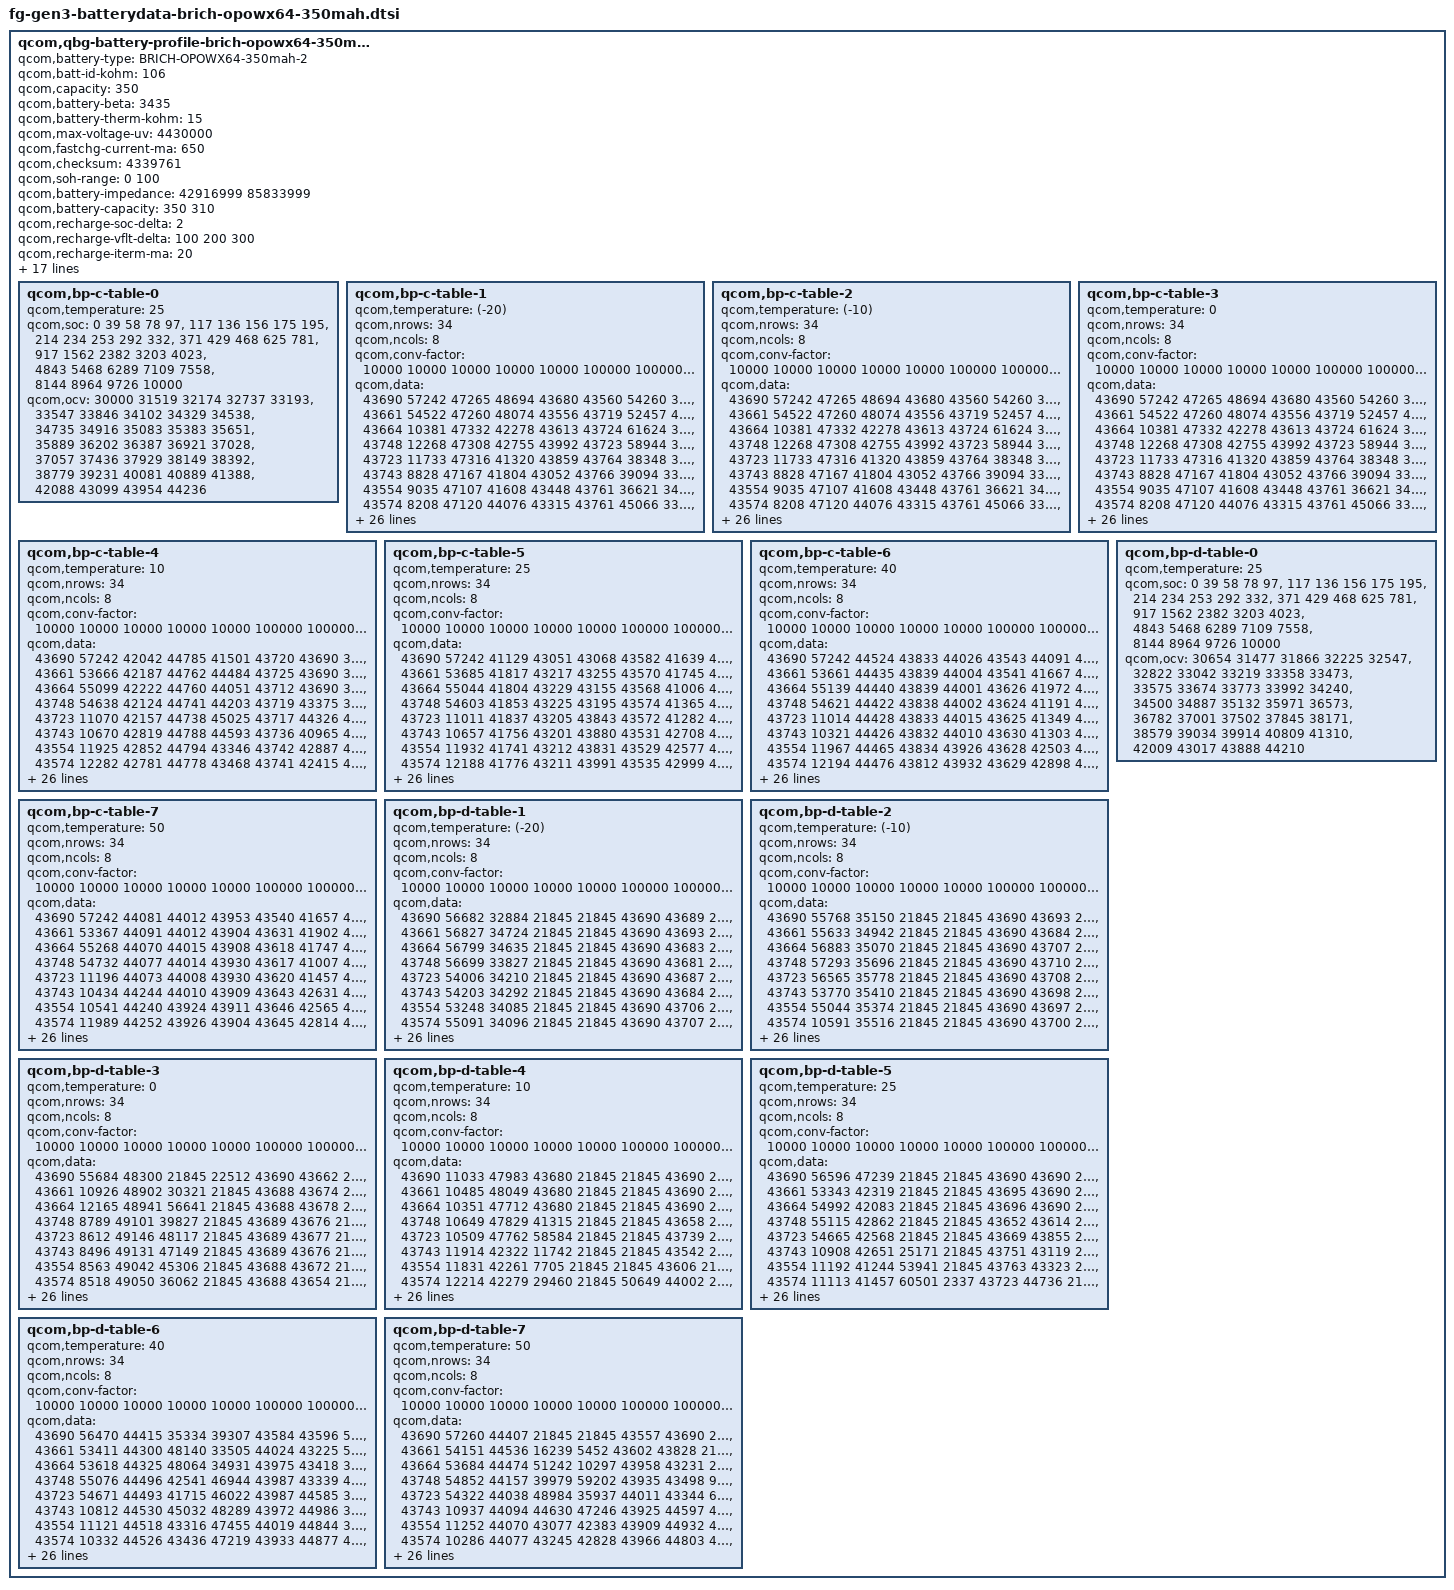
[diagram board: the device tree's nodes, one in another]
qcom,qbg-battery-profile-brich-opowx64-350mAh {
	qcom,battery-type = "BRICH-OPOWX64-350mah-2";
	qcom,batt-id-kohm = <106>;
	qcom,capacity = <350>;
	qcom,battery-beta = <3435>;
	qcom,battery-therm-kohm = <15>;
	qcom,max-voltage-uv = <4430000>;
	qcom,fastchg-current-ma = <650>;
	qcom,checksum = <4339761>; /*@5, 0.008V, 8.0% */
	qcom,soh-range = <0 100>;
	/* Nominal_Impedance in 10nohm @ SOC 50% 25C* 0:fresh cell, 1: aged cell */
	qcom,battery-impedance = <42916999 85833999>;
	/* Nominal_Capacity in mAh. 0: fresh cell, 1:aged cell */
	qcom,battery-capacity = <350 310>;
	/* SOC delta (in percent) dropped from EOC SOC to enable recharge */
	qcom,recharge-soc-delta =<2>;
	/* vfloat delta (in mV) dropped from regular vfloat in recharge */
	qcom,recharge-vflt-delta =<100 200 300>;
	/* Termination current (in mA) in recharge */
	qcom,recharge-iterm-ma = <20>;
	qcom,batt-temp-coeffs =    <0 70 120 170 430 435 440 530>;
	qcom,batt-current-coeffs = <0 150000 225000 300000 650000 350000 100000 100000>;
	qcom,batt-max-mv-coeffs = <4130000 4430000>;
	qcom,chg-limit-current-default = <100000 150000>;

	qcom,jeita-fcc-ranges = <0  70  150000
                                71 440  650000
                                441 530 100000>;

    	qcom,jeita-fv-ranges = <0   70  4430000
                           	71 440  4430000
                           	441 530 4130000>;
				
	qcom,step-chg-ranges = <3400000  4250000  650000
				4250001  4350000  650000
				4350001  4430000  650000>;

    /* COOL = 15 DegC, WARM = 70 DegC */
    qcom,jeita-soft-thresholds = <0x30DD 0x7BC>;
    /* COLD = 0 DegC, HOT = 80 DegC */
    qcom,jeita-hard-thresholds = <0x3733 0x5ed>;
    /* COOL = 18 DegC, WARM = 39 DegC*/
    qcom,jeita-soft-hys-thresholds = <0x256e 0x161b>;
    qcom,jeita-soft-fcc-ua = <150000 100000>;
    qcom,jeita-soft-fv-uv = <4430000 4430000>;

	qcom,bp-c-table-0 {
		qcom,temperature = <25>;
		qcom,soc = <    0    39    58    78    97>,
			<  117   136   156   175   195>,
			<  214   234   253   292   332>,
			<  371   429   468   625   781>,
			<  917  1562  2382  3203  4023>,
			< 4843  5468  6289  7109  7558>,
			< 8144  8964  9726 10000>;
		qcom,ocv = <30000 31519 32174 32737 33193>,
			<33547 33846 34102 34329 34538>,
			<34735 34916 35083 35383 35651>,
			<35889 36202 36387 36921 37028>,
			<37057 37436 37929 38149 38392>,
			<38779 39231 40081 40889 41388>,
			<42088 43099 43954 44236>;
	};

	qcom,bp-c-table-1 {
		qcom,temperature = <(-20)>;
		qcom,nrows = <34>;
		qcom,ncols = <8>;
		qcom,conv-factor = <10000 10000 10000 10000 10000 100000 100000 10000>;
		qcom,data = <43690 57242 47265 48694 43680 43560 54260 37818>,
			<43661 54522 47260 48074 43556 43719 52457 40812>,
			<43664 10381 47332 42278 43613 43724 61624 39259>,
			<43748 12268 47308 42755 43992 43723 58944 39098>,
			<43723 11733 47316 41320 43859 43764 38348 39578>,
			<43743  8828 47167 41804 43052 43766 39094 33995>,
			<43554  9035 47107 41608 43448 43761 36621 34309>,
			<43574  8208 47120 44076 43315 43761 45066 33153>,
			<43525  8666 47213 44983 44729 43766 47882 33608>,
			<43625  9892 47204 43357 44752 43767 41365 33353>,
			<43644  9739 47226 43446 44647 43764 44360 33437>,
			<43584 10114 47204 43239 44933 43720 45014 36121>,
			<43607  9992 47200 43820 44854 43725 43486 36334>,
			<43918  9438 47125 43714 44268 43737 43590 35893>,
			<44006  9612 47105 43664 44286 43735 43531 35998>,
			<43993  9581 47144 43678 44264 43554 43531 36684>,
			<43783 15093 47353 43672 44189 43579 43531 36667>,
			<43902 14909 47342 43672 44182 43576 43573 36812>,
			<43227 14918 47302 43753 44279 43733 43532 36784>,
			<43431 15295 47351 43008 44764 43734 43471 36859>,
			<43327 15255 47262 44952 43260 43563 44384 36619>,
			<44208 14777 47293 44287 44735 43552 41203 35951>,
			<41956 15995 47938 44120 44160 43578 41196 36101>,
			<42537 16171 47928 44485 44157 43578 41066 36166>,
			<42269 15552 47905 44402 44132 43558 41803 36217>,
			<47169 15722 47919 44348 41641 43558 44486 33437>,
			<49142 13269 47918 44342 44522 43555 41813 36286>,
			<45627 13836 47701 44510 44827 43567 44191 36370>,
			<45423 13595 47698 44393 44956 43560 44122 36562>,
			<46892  2858 47687 44380 44996 43563 44241 36445>,
			<46458  3749 47685 41678 44868 43562 44196 35981>,
			<35246  3445 48005 41559 40979 43563 43342 34028>,
			<36692   492 47978 44121 48695 43560 43136 36954>,
			<36282  1778 48083 44684 48125 43712 43933 40443>;
	};

	qcom,bp-c-table-2 {
		qcom,temperature = <(-10)>;
		qcom,nrows = <34>;
		qcom,ncols = <8>;
		qcom,conv-factor = <10000 10000 10000 10000 10000 100000 100000 10000>;
		qcom,data = <43690 57242 47265 48694 43680 43560 54260 37818>,
			<43661 54522 47260 48074 43556 43719 52457 40812>,
			<43664 10381 47332 42278 43613 43724 61624 39259>,
			<43748 12268 47308 42755 43992 43723 58944 39098>,
			<43723 11733 47316 41320 43859 43764 38348 39578>,
			<43743  8828 47167 41804 43052 43766 39094 33995>,
			<43554  9035 47107 41608 43448 43761 36621 34309>,
			<43574  8208 47120 44076 43315 43761 45066 33153>,
			<43525  8666 47213 44983 44729 43766 47882 33608>,
			<43625  9892 47204 43357 44752 43767 41365 33353>,
			<43644  9739 47226 43446 44647 43764 44360 33437>,
			<43584 10114 47204 43239 44933 43720 45014 36121>,
			<43607  9992 47200 43820 44854 43725 43486 36334>,
			<43918  9438 47125 43714 44268 43737 43590 35893>,
			<44006  9612 47105 43664 44286 43735 43531 35998>,
			<43993  9581 47144 43678 44264 43554 43531 36684>,
			<43783 15093 47353 43672 44189 43579 43531 36667>,
			<43902 14909 47342 43672 44182 43576 43573 36812>,
			<43227 14918 47302 43753 44279 43733 43532 36784>,
			<43431 15295 47351 43008 44764 43734 43471 36859>,
			<43327 15255 47262 44952 43260 43563 44384 36619>,
			<44208 14777 47293 44287 44735 43552 41203 35951>,
			<41956 15995 47938 44120 44160 43578 41196 36101>,
			<42537 16171 47928 44485 44157 43578 41066 36166>,
			<42269 15552 47905 44402 44132 43558 41803 36217>,
			<47169 15722 47919 44348 41641 43558 44486 33437>,
			<49142 13269 47918 44342 44522 43555 41813 36286>,
			<45627 13836 47701 44510 44827 43567 44191 36370>,
			<45423 13595 47698 44393 44956 43560 44122 36562>,
			<46892  2858 47687 44380 44996 43563 44241 36445>,
			<46458  3749 47685 41678 44868 43562 44196 35981>,
			<35246  3445 48005 41559 40979 43563 43342 34028>,
			<36692   492 47978 44121 48695 43560 43136 36954>,
			<36282  1778 48083 44684 48125 43712 43933 40443>;
	};

	qcom,bp-c-table-3 {
		qcom,temperature = <0>;
		qcom,nrows = <34>;
		qcom,ncols = <8>;
		qcom,conv-factor = <10000 10000 10000 10000 10000 100000 100000 10000>;
		qcom,data = <43690 57242 47265 48694 43680 43560 54260 37818>,
			<43661 54522 47260 48074 43556 43719 52457 40812>,
			<43664 10381 47332 42278 43613 43724 61624 39259>,
			<43748 12268 47308 42755 43992 43723 58944 39098>,
			<43723 11733 47316 41320 43859 43764 38348 39578>,
			<43743  8828 47167 41804 43052 43766 39094 33995>,
			<43554  9035 47107 41608 43448 43761 36621 34309>,
			<43574  8208 47120 44076 43315 43761 45066 33153>,
			<43525  8666 47213 44983 44729 43766 47882 33608>,
			<43625  9892 47204 43357 44752 43767 41365 33353>,
			<43644  9739 47226 43446 44647 43764 44360 33437>,
			<43584 10114 47204 43239 44933 43720 45014 36121>,
			<43607  9992 47200 43820 44854 43725 43486 36334>,
			<43918  9438 47125 43714 44268 43737 43590 35893>,
			<44006  9612 47105 43664 44286 43735 43531 35998>,
			<43993  9581 47144 43678 44264 43554 43531 36684>,
			<43783 15093 47353 43672 44189 43579 43531 36667>,
			<43902 14909 47342 43672 44182 43576 43573 36812>,
			<43227 14918 47302 43753 44279 43733 43532 36784>,
			<43431 15295 47351 43008 44764 43734 43471 36859>,
			<43327 15255 47262 44952 43260 43563 44384 36619>,
			<44208 14777 47293 44287 44735 43552 41203 35951>,
			<41956 15995 47938 44120 44160 43578 41196 36101>,
			<42537 16171 47928 44485 44157 43578 41066 36166>,
			<42269 15552 47905 44402 44132 43558 41803 36217>,
			<47169 15722 47919 44348 41641 43558 44486 33437>,
			<49142 13269 47918 44342 44522 43555 41813 36286>,
			<45627 13836 47701 44510 44827 43567 44191 36370>,
			<45423 13595 47698 44393 44956 43560 44122 36562>,
			<46892  2858 47687 44380 44996 43563 44241 36445>,
			<46458  3749 47685 41678 44868 43562 44196 35981>,
			<35246  3445 48005 41559 40979 43563 43342 34028>,
			<36692   492 47978 44121 48695 43560 43136 36954>,
			<36282  1778 48083 44684 48125 43712 43933 40443>;
	};

	qcom,bp-c-table-4 {
		qcom,temperature = <10>;
		qcom,nrows = <34>;
		qcom,ncols = <8>;
		qcom,conv-factor = <10000 10000 10000 10000 10000 100000 100000 10000>;
		qcom,data = <43690 57242 42042 44785 41501 43720 43690 36500>,
			<43661 53666 42187 44762 44484 43725 43690 34999>,
			<43664 55099 42222 44760 44051 43712 43690 35748>,
			<43748 54638 42124 44741 44203 43719 43375 35497>,
			<43723 11070 42157 44738 45025 43717 44326 46507>,
			<43743 10670 42819 44788 44593 43736 40965 46240>,
			<43554 11925 42852 44794 43346 43742 42887 46985>,
			<43574 12282 42781 44778 43468 43741 42415 46820>,
			<43525 11497 42767 44676 43072 43728 47762 45349>,
			<43625 11656 42803 44723 43041 43734 47726 45123>,
			<43644 11614 42814 44715 43244 43733 47835 45296>,
			<43584  8732 42810 43381 43183 43560 42105 45945>,
			<43607  9155 42789 43283 43879 43566 42541 46066>,
			<43918  8204 42788 43479 43810 43555 41475 45578>,
			<44006  8477 42798 43456 43819 43558 41634 45801>,
			<43993  9742 42958 43466 43988 43556 44384 45743>,
			<43783 10103 42981 43488 43817 43576 44420 48491>,
			<43902  9277 42900 43417 43838 43580 44247 48436>,
			<43227 14889 42928 43500 44022 43583 41682 48562>,
			<43431 14949 42917 43507 43971 43580 41902 48223>,
			<43327 14917 42580 43510 43779 43580 41509 48570>,
			<44208 14546 42615 44680 43298 43528 41883 45585>,
			<41956 16083 42497 44600 44965 43535 41832 45923>,
			<42537 16284 42693 44664 45046 43534 41171 45946>,
			<42269 15537 42693 44941 44936 43573 41140 45873>,
			<47169 15651 42642 45053 45023 43574 44140 45947>,
			<49142 13235 42668 44966 44119 43573 41638 45105>,
			<45627 13834 41313 44645 43279 43581 44459 48128>,
			<45423 13580 41234 44615 43282 43581 44255 48146>,
			<46892  2849 41245 44960 43355 43581 44892 48574>,
			<46458  3740 41228 44955 44751 43583 45041 48505>,
			<35246   654 41343 44893 44214 43583 44567 45136>,
			<36692   298 42638 44619 42524 43569 43058 34981>,
			<36282  1591 41292 43037 42979 43578 44023 35793>;
	};

	qcom,bp-c-table-5 {
		qcom,temperature = <25>;
		qcom,nrows = <34>;
		qcom,ncols = <8>;
		qcom,conv-factor = <10000 10000 10000 10000 10000 100000 100000 10000>;
		qcom,data = <43690 57242 41129 43051 43068 43582 41639 47964>,
			<43661 53685 41817 43217 43255 43570 41745 48075>,
			<43664 55044 41804 43229 43155 43568 41006 48057>,
			<43748 54603 41853 43225 43195 43574 41365 47725>,
			<43723 11011 41837 43205 43843 43572 41282 47830>,
			<43743 10657 41756 43201 43880 43531 42708 47775>,
			<43554 11932 41741 43212 43831 43529 42577 42328>,
			<43574 12188 41776 43211 43991 43535 42999 42268>,
			<43525 11443 41786 43254 43977 43532 42763 42280>,
			<43625 11328 41760 43260 44027 43522 42857 42482>,
			<43644 11525 41762 43258 44002 43523 42775 42396>,
			<43584  8910 41762 43235 44011 43521 42955 42416>,
			<43607  9121 41773 43240 43921 43527 42618 42411>,
			<43918  8349 41772 43164 43929 43525 41313 42098>,
			<44006  8681 41939 43162 43908 43547 41273 42009>,
			<43993  9883 41975 43142 43905 43545 41420 42046>,
			<43783 10176 41957 43142 43908 43551 41409 42025>,
			<43902  9353 41958 43160 43934 43548 41322 42027>,
			<43227 14995 41881 43176 43928 43541 41406 42167>,
			<43431 14862 41866 43844 43927 43542 41415 42846>,
			<43327 14955 41910 43844 43985 43541 41983 42123>,
			<44208 14486 41537 43257 43074 43540 44305 42303>,
			<41956 16003 41579 43014 43357 43627 41925 47616>,
			<42537 16303 41480 43115 43284 43537 41196 47841>,
			<42269 16210 41669 43450 43324 43548 41897 47851>,
			<47169 15825 41710 43466 43378 43551 44879 47631>,
			<49142 13205 41649 43121 44665 43545 44961 47689>,
			<45627 13883 44378 43067 43204 43527 44044 42825>,
			<45423 13587 44392 43015 43227 43526 44864 42864>,
			<46892  2822 44315 43026 43038 43521 44951 42163>,
			<46458  3778 44343 43124 43444 43520 44632 41993>,
			<35246   753 44303 43417 43359 43520 44545 42330>,
			<36692   280 44397 43454 41879 43545 43453 49122>,
			<36282  1638 44330 43896 44356 43631 43848 47120>;
	};

	qcom,bp-c-table-6 {
		qcom,temperature = <40>;
		qcom,nrows = <34>;
		qcom,ncols = <8>;
		qcom,conv-factor = <10000 10000 10000 10000 10000 100000 100000 10000>;
		qcom,data = <43690 57242 44524 43833 44026 43543 44091 41387>,
			<43661 53661 44435 43839 44004 43541 41667 41024>,
			<43664 55139 44440 43839 44001 43626 41972 41076>,
			<43748 54621 44422 43838 44002 43624 41191 41083>,
			<43723 11014 44428 43833 44015 43625 41349 41070>,
			<43743 10321 44426 43832 44010 43630 41303 40989>,
			<43554 11967 44465 43834 43926 43628 42503 40963>,
			<43574 12194 44476 43812 43932 43629 42898 41008>,
			<43525 12149 44475 43814 43931 43618 42815 40998>,
			<43625 11267 44455 43811 43905 43619 42772 41175>,
			<43644 11712 44451 43820 43918 43616 42753 41158>,
			<43584  8881 44463 43818 43953 43622 42949 41202>,
			<43607  8725 44456 43984 43960 43623 42889 41199>,
			<43918  9037 44118 43993 43951 43621 42603 41088>,
			<44006  8260 44114 43999 43946 43640 42955 41098>,
			<43993  8562 44127 43984 43606 43647 42029 41136>,
			<43783 10149 44101 43984 43607 43645 42099 41145>,
			<43902 10092 44096 43997 43605 43634 42043 41126>,
			<43227  9537 44148 44025 43611 43584 42706 41833>,
			<43431 15042 44146 43916 43591 43609 41258 41763>,
			<43327 14891 44133 43931 43930 43615 41724 41842>,
			<44208 15217 44053 43837 43848 43591 41849 41034>,
			<41956 14608 44058 43830 43042 43589 41504 41437>,
			<42537 15982 44092 43812 43174 43639 41853 41032>,
			<42269 16230 44253 43903 43860 43640 41637 41385>,
			<47169 15820 44287 43189 43261 43619 44822 41265>,
			<49142 13287 44180 43841 43009 43646 44936 41270>,
			<45627 13874 44208 43983 44004 43638 44083 41951>,
			<45423 13665 44882 43839 43998 43638 44479 41757>,
			<46892  2924 44866 43778 43800 43644 44277 41822>,
			<46458  3630 44924 43898 43182 43640 44176 41167>,
			<35246   711 44901 43180 43068 43622 44868 41349>,
			<36692   286 44913 43187 44941 43647 44550 42157>,
			<36282  1610 44838 43915 44943 43598 43151 42719>;
	};

	qcom,bp-c-table-7 {
		qcom,temperature = <50>;
		qcom,nrows = <34>;
		qcom,ncols = <8>;
		qcom,conv-factor = <10000 10000 10000 10000 10000 100000 100000 10000>;
		qcom,data = <43690 57242 44081 44012 43953 43540 41657 41737>,
			<43661 53367 44091 44012 43904 43631 41902 41742>,
			<43664 55268 44070 44015 43908 43618 41747 41739>,
			<43748 54732 44077 44014 43930 43617 41007 41783>,
			<43723 11196 44073 44008 43930 43620 41457 41789>,
			<43743 10434 44244 44010 43909 43643 42631 41786>,
			<43554 10541 44240 43924 43911 43646 42565 41773>,
			<43574 11989 44252 43926 43904 43645 42814 41943>,
			<43525 12278 44249 43923 43916 43635 42148 41945>,
			<43625 11392 44250 43932 43915 43638 42235 41933>,
			<43644 11335 44231 43929 43953 43636 42191 41968>,
			<43584 11530 44224 43908 43960 43594 42203 41954>,
			<43607  8940 44226 43904 43949 43592 42194 41884>,
			<43918  9179 44238 43913 43602 43596 42017 41904>,
			<44006  8401 44235 43912 43614 43586 42089 41893>,
			<43993  8643 44276 43915 43608 43585 42424 41901>,
			<43783  9737 44272 43915 43591 43588 42282 41553>,
			<43902 10230 44285 43915 43586 43610 42319 41560>,
			<43227  9532 44263 43966 43644 43944 42281 41578>,
			<43431 15002 44268 43632 43628 43955 41326 41669>,
			<43327 15085 44268 43615 43611 43967 41874 41491>,
			<44208 15162 44180 43924 43995 43937 41016 41942>,
			<41956 14791 44187 44005 43895 43966 41921 41796>,
			<42537 15881 44214 43912 43996 43949 41746 41957>,
			<42269 16235 44206 44021 43987 43609 44415 41774>,
			<47169 15808 44866 43784 43898 43593 44905 41145>,
			<49142 13302 44926 43823 43841 43611 44854 41820>,
			<45627 13834 44824 43967 43610 43944 41592 41722>,
			<45423 13684 44858 43911 43931 43605 44332 41508>,
			<46892  2928 45012 44006 43979 43613 44308 41594>,
			<46458  3632 44999 43980 43779 43608 44434 41871>,
			<35246   722 45041 43828 43193 43590 44505 41750>,
			<36692   278 45054 43788 43361 43589 44625 41425>,
			<36282  1613 44658 43821 43429 43590 43343 41116>;
	};

	qcom,bp-d-table-0 {
		qcom,temperature = <25>;
		qcom,soc = <    0    39    58    78    97>,
			<  117   136   156   175   195>,
			<  214   234   253   292   332>,
			<  371   429   468   625   781>,
			<  917  1562  2382  3203  4023>,
			< 4843  5468  6289  7109  7558>,
			< 8144  8964  9726 10000>;
		qcom,ocv = <30654 31477 31866 32225 32547>,
			<32822 33042 33219 33358 33473>,
			<33575 33674 33773 33992 34240>,
			<34500 34887 35132 35971 36573>,
			<36782 37001 37502 37845 38171>,
			<38579 39034 39914 40809 41310>,
			<42009 43017 43888 44210>;
	};

	qcom,bp-d-table-1 {
		qcom,temperature = <(-20)>;
		qcom,nrows = <34>;
		qcom,ncols = <8>;
		qcom,conv-factor = <10000 10000 10000 10000 10000 100000 100000 10000>;
		qcom,data = <43690 56682 32884 21845 21845 43690 43689 21845>,
			<43661 56827 34724 21845 21845 43690 43693 21845>,
			<43664 56799 34635 21845 21845 43690 43683 21845>,
			<43748 56699 33827 21845 21845 43690 43681 21845>,
			<43723 54006 34210 21845 21845 43690 43687 21845>,
			<43743 54203 34292 21845 21845 43690 43684 21845>,
			<43554 53248 34085 21845 21845 43690 43706 21845>,
			<43574 55091 34096 21845 21845 43690 43707 21845>,
			<43525 11012 34267 21845 21845 43690 43704 21845>,
			<43625 11347 33878 21845 21845 43690 43705 21845>,
			<43644  8529 33994 21845 21845 43690 43710 21845>,
			<43584  9477 34580 21845 21845 43690 43710 21845>,
			<43607 14567 34714 21845 21845 43690 43710 21845>,
			<43918 16037 34363 21845 21845 43690 43711 21845>,
			<44006 15878 34438 21845 21845 43690 43711 21845>,
			<43993 14613 33126 21845 21845 43690 43710 21845>,
			<43783 14928 33213 21845 21845 43690 43706 21845>,
			<43902 15046 32868 21845 21845 43690 43706 21845>,
			<43227 15241 33651 21845 21845 43690 43702 21845>,
			<43431  9499 33408 21845 42982 43682 44358 21845>,
			<43327 14904 36154 21845 56469 43693 43416 21845>,
			<44208 15284 36829  2742 47649 43695 43219 21845>,
			<41956 14557 35955 49252 42422 43688 43233 21845>,
			<42537 14603 36824 57393 42192 43688 43242 16575>,
			<42269 15929 36716 40634 42762 43688 43176 25774>,
			<47169 16160 36688 35979 42925 43688 43845  4506>,
			<49142 15413 36644 46182 42799 43689 43870  6792>,
			<45627 13182 36811 46438 48724 43694 44599  6425>,
			<45423 13514 36627 35716 35974 43693 44164 27110>,
			<46892  2571 36025 46374 33956 43687 43345 25348>,
			<46458  2266 36772 47076 35047 43665 43451  5194>,
			<35246  3162 36773 46386 35630 43744 44757 27049>,
			<36692    72 36382 33335 45441 43690 43551  5126>,
			<36282  1623 36411 34558 45830 43690 43690  4138>;
	};

	qcom,bp-d-table-2 {
		qcom,temperature = <(-10)>;
		qcom,nrows = <34>;
		qcom,ncols = <8>;
		qcom,conv-factor = <10000 10000 10000 10000 10000 100000 100000 10000>;
		qcom,data = <43690 55768 35150 21845 21845 43690 43693 21845>,
			<43661 55633 34942 21845 21845 43690 43684 21845>,
			<43664 56883 35070 21845 21845 43690 43707 21845>,
			<43748 57293 35696 21845 21845 43690 43710 21845>,
			<43723 56565 35778 21845 21845 43690 43708 21845>,
			<43743 53770 35410 21845 21845 43690 43698 21845>,
			<43554 55044 35374 21845 21845 43690 43697 21845>,
			<43574 10591 35516 21845 21845 43690 43700 21845>,
			<43525  9058 46365 21845 21845 43690 43658 21845>,
			<43625 10199 46554 21845 21845 43690 43659 21845>,
			<43644  9375 46569 21845 21845 43690 43659 21845>,
			<43584  9463 46516 21845 21845 43690 43701 21845>,
			<43607  9419 46164 21845 21845 43690 43702 21845>,
			<43918  9422 46187 18257 21845 43690 43709 21845>,
			<44006  9290 46293 32668 21845 43690 43709 21845>,
			<43993  9508 46232  5297 21845 43690 43696 21845>,
			<43783  9577 46898 28519 21845 43691 43582 21845>,
			<43902  9689 46687 21845 30743 43694 43189 21845>,
			<43227  9700 46846 32489 42613 43683 44179 21845>,
			<43431  9515 46832  6388 42626 43689 43111 21845>,
			<43327  9497 45530 15168 42666 43688 43153 21845>,
			<44208 15285 45415 59616 41266 43688 43102  5254>,
			<41956 14433 45312 35358 42655 43689 43121 14406>,
			<42537 14695 45328 47264 41208 43695 43032 56442>,
			<42269 15908 45333 41304 41535 43683 43151 52938>,
			<47169 16227 45531 41821 44357 43666 44568 61726>,
			<49142 15738 45437 41345 42914 43713 44056 62481>,
			<45627 12706 45541 42949 47424 43734 44814 52916>,
			<45423 13821 45510 42204 34957 43739 43267 55924>,
			<46892  2663 45507 47782 45200 43717 43036 49172>,
			<46458  2316 45449 47935 45628 43726 43352 49476>,
			<35246  3390 45148 48070 45673 43714 44732 50605>,
			<36692   505 45086 47848 47834 43767 43376 49623>,
			<36282  1625 45094 42358 42173 43760 43388 49820>;
	};

	qcom,bp-d-table-3 {
		qcom,temperature = <0>;
		qcom,nrows = <34>;
		qcom,ncols = <8>;
		qcom,conv-factor = <10000 10000 10000 10000 10000 100000 100000 10000>;
		qcom,data = <43690 55684 48300 21845 22512 43690 43662 21845>,
			<43661 10926 48902 30321 21845 43688 43674 21845>,
			<43664 12165 48941 56641 21845 43688 43678 21845>,
			<43748  8789 49101 39827 21845 43689 43676 21845>,
			<43723  8612 49146 48117 21845 43689 43677 21845>,
			<43743  8496 49131 47149 21845 43689 43676 21845>,
			<43554  8563 49042 45306 21845 43688 43672 21845>,
			<43574  8518 49050 36062 21845 43688 43654 21845>,
			<43525  8519 49037 40917 21845 43691 43661 21845>,
			<43625  8537 49072 60586 21845 43691 43663 21845>,
			<43644  9893 49067 61681 21845 43691 43720 21845>,
			<43584  9858 48742 54821 21845 43694 43831 21845>,
			<43607  9879 48686  3657 24933 43682 43469 21845>,
			<43918  9947 47443 19285 45333 43684 44228 21845>,
			<44006  9846 47367 19047 42326 43687 44266 21845>,
			<43993 10041 47558 26525 42366 43682 44670 21845>,
			<43783  9470 47588  1770 42458 43689 43510 21845>,
			<43902  9225 47584  9492 42073 43688 43119 24575>,
			<43227  9616 47577 59658 41218 43688 43020  6568>,
			<43431  9514 47557 33281 41729 43688 43110  9639>,
			<43327  9476 47564 46199 41868 43689 43115 54747>,
			<44208 15308 47523 42958 41961 43693 44718 61578>,
			<41956 14737 47168 44331 41971 43724 44192 61059>,
			<42537 14709 47539 44222 44940 43740 44631 39251>,
			<42269 15878 47170 45018 44799 43728 45020 34664>,
			<47169 15418 47154 44072 44361 43567 44460 34232>,
			<49142 13019 47154 44453 41169 43559 44284 39524>,
			<45627 13979 47325 41585 48720 43579 45024 38550>,
			<45423 13780 47326 41824 47279 43567 43118 37705>,
			<46892  3016 47354 41205 42182 43731 43302 40249>,
			<46458  3772 47256 41206 42850 43730 44685 40246>,
			<35246  3412 47348 41735 42418 43735 44774 37093>,
			<36692   464 47236 41512 41363 43563 44712 40275>,
			<36282  1603 47269 44372 41877 43560 43382 40529>;
	};

	qcom,bp-d-table-4 {
		qcom,temperature = <10>;
		qcom,nrows = <34>;
		qcom,ncols = <8>;
		qcom,conv-factor = <10000 10000 10000 10000 10000 100000 100000 10000>;
		qcom,data = <43690 11033 47983 43680 21845 21845 43690 21845>,
			<43661 10485 48049 43680 21845 21845 43690 21845>,
			<43664 10351 47712 43680 21845 21845 43690 21845>,
			<43748 10649 47829 41315 21845 21845 43658 21845>,
			<43723 10509 47762 58584 21845 21845 43739 21845>,
			<43743 11914 42322 11742 21845 21845 43542 21845>,
			<43554 11831 42261  7705 21845 21845 43606 21845>,
			<43574 12214 42279 29460 21845 50649 44002 21845>,
			<43525 12086 42442 23642 21845 43656 43788 21845>,
			<43625 11401 42399 21845  2705 43706 43182 21845>,
			<43644 11294 42401 21924 65127 43706 43262 21845>,
			<43584 11747 42057 17351 39100 43685 43219 21845>,
			<43607 11633 42006 24814 33712 43684 43231 21845>,
			<43918  8781 42198 14004 46556 43682 43255 23788>,
			<44006  9033 42237 53872 45207 43689 43237 30254>,
			<43993  8293 42231 62347 48143 43688 43254 27618>,
			<43783  9914 42029 33829 47546 43688 43044 15450>,
			<43902  9848 42016 35807 47900 43688 43027 10257>,
			<43227  9334 42197 47671 42040 43682 43498 63158>,
			<43431  9681 42187 41092 41102 43709 43272 60521>,
			<43327  9488 42201 44379 41644 43660 44680 37279>,
			<44208 15288 42221 45045 44449 43749 44572 33188>,
			<41956 14419 42821 44745 44926 43554 44871 35444>,
			<42537 14694 42785 43381 44728 43576 44113 45343>,
			<42269 15967 42971 44735 44966 43530 44493 45374>,
			<47169 15370 42906 44693 45040 43572 44086 45473>,
			<49142 13010 42922 44550 44470 43572 44236 46619>,
			<45627 13991 42589 44802 42780 43528 43378 36541>,
			<45423 13764 42623 44224 41790 43554 43123 35419>,
			<46892  3018 42922 44281 41629 43560 43478 46357>,
			<46458  3766 42591 44208 44410 43566 44683 46344>,
			<35246   679 42583 44923 41595 43559 44750 35639>,
			<36692   469 42880 45002 44351 43570 44566 35608>,
			<36282  1663 42997 44954 44286 43575 44671 35638>;
	};

	qcom,bp-d-table-5 {
		qcom,temperature = <25>;
		qcom,nrows = <34>;
		qcom,ncols = <8>;
		qcom,conv-factor = <10000 10000 10000 10000 10000 100000 100000 10000>;
		qcom,data = <43690 56596 47239 21845 21845 43690 43690 21845>,
			<43661 53343 42319 21845 21845 43695 43690 21845>,
			<43664 54992 42083 21845 21845 43696 43690 21845>,
			<43748 55115 42862 21845 21845 43652 43614 21845>,
			<43723 54665 42568 21845 21845 43669 43855 21845>,
			<43743 10908 42651 25171 21845 43751 43119 21845>,
			<43554 11192 41244 53941 21845 43763 43323 21845>,
			<43574 11113 41457 60501  2337 43723 44736 21845>,
			<43525 10468 41399 39110 55454 43714 44959 24999>,
			<43625 10347 41029 36404 62141 43716 44868 13975>,
			<43644 10637 41082 45489 60505 43742 44254 55198>,
			<43584 10528 40981 49101 38463 43729 44039 49178>,
			<43607 10567 40984 47913 40465 43567 44155 63377>,
			<43918 11874 41009 42602 33535 43574 44459 58136>,
			<44006 12138 41007 41798 46484 43527 44473 38648>,
			<43993 11374 41165 41609 45603 43545 44455 38942>,
			<43783  8941 41199 44241 47955 43547 44125 33667>,
			<43902  9110 41108 44896 42397 43523 44102 36782>,
			<43227  9769 41798 44770 41876 43557 44093 45391>,
			<43431  9335 41827 43293 44494 43556 45032 45608>,
			<43327  9476 41734 43463 44157 43580 44647 48545>,
			<44208 14883 41951 43201 43514 43534 45037 48091>,
			<41956 14548 41881 43139 43087 43538 44476 42311>,
			<42537 14719 41902 43157 44792 43542 44153 47705>,
			<42269 16305 41568 43208 43335 43628 44200 47841>,
			<47169 15385 41533 43263 43420 43545 44818 42391>,
			<49142 13008 41681 43058 44687 43524 44821 47864>,
			<45627 12608 41717 43296 44110 43550 43278 47429>,
			<45423 13763 41703 43478 44581 43571 43519 47934>,
			<46892  3060 41704 43404 43391 43581 43461 47657>,
			<46458  3763 41618 43426 43510 43583 44734 42310>,
			<35246   675 41708 43122 43468 43571 44757 42313>,
			<36692   474 41674 43066 43270 43527 44573 47800>,
			<36282  1560 41670 43231 43374 43545 44646 47756>;
	};

	qcom,bp-d-table-6 {
		qcom,temperature = <40>;
		qcom,nrows = <34>;
		qcom,ncols = <8>;
		qcom,conv-factor = <10000 10000 10000 10000 10000 100000 100000 10000>;
		qcom,data = <43690 56470 44415 35334 39307 43584 43596 52088>,
			<43661 53411 44300 48140 33505 44024 43225 57426>,
			<43664 53618 44325 48064 34931 43975 43418 38399>,
			<43748 55076 44496 42541 46944 43987 43339 40494>,
			<43723 54671 44493 41715 46022 43987 44585 33174>,
			<43743 10812 44530 45032 48289 43972 44986 36508>,
			<43554 11121 44518 43316 47455 44019 44844 35456>,
			<43574 10332 44526 43436 47219 43933 44877 46328>,
			<43525 10584 44439 43068 47955 43937 44176 46659>,
			<43625 11877 44445 43257 48110 43592 44073 45428>,
			<43644 12094 44443 43142 47617 43627 44140 45473>,
			<43584 11502 44422 43192 47800 43546 44450 45205>,
			<43607 11343 44418 43179 42482 43525 44513 46065>,
			<43918 11607 44427 43847 42993 43546 44384 48534>,
			<44006  8794 44465 43851 41058 43550 41608 48650>,
			<43993  9060 44479 43897 41618 43539 41698 47953>,
			<43783  8623 44454 43793 44993 43541 41715 42412>,
			<43902  8551 44461 43802 44744 43541 41666 42829>,
			<43227  9436 44117 43776 43009 43617 41593 42681>,
			<43431  9481 44125 43776 43196 43643 44272 41428>,
			<43327  9586 44123 43998 43872 43635 44823 41030>,
			<44208 14874 44146 43921 43977 43584 44339 41089>,
			<41956 14544 44143 43958 43792 43614 44077 41109>,
			<42537 16034 44041 44014 43489 43947 45036 41343>,
			<42269 16273 44072 43922 43249 43602 44609 40979>,
			<47169 15461 44224 43926 43903 43611 44912 41142>,
			<49142 12853 44284 43812 43104 43599 44264 41463>,
			<45627 14011 44265 43153 44708 43625 44707 42953>,
			<45423 13794 44160 43841 43139 43540 44774 41400>,
			<46892  2965 44171 43895 43881 43537 44994 41018>,
			<46458  2397 44208 43797 43986 43627 44246 41142>,
			<35246  3401 44217 43810 43999 43623 44041 41849>,
			<36692   485 44196 44027 43887 43636 44220 41825>,
			<36282  1598 44198 43927 43852 43593 44924 41850>;
	};

	qcom,bp-d-table-7 {
		qcom,temperature = <50>;
		qcom,nrows = <34>;
		qcom,ncols = <8>;
		qcom,conv-factor = <10000 10000 10000 10000 10000 100000 100000 10000>;
		qcom,data = <43690 57260 44407 21845 21845 43557 43690 21845>,
			<43661 54151 44536 16239  5452 43602 43828 21845>,
			<43664 53684 44474 51242 10297 43958 43231 23150>,
			<43748 54852 44157 39979 59202 43935 43498  9365>,
			<43723 54322 44038 48984 35937 44011 43344 61319>,
			<43743 10937 44094 44630 47246 43925 44597 46189>,
			<43554 11252 44070 43077 42383 43909 44932 45862>,
			<43574 10286 44077 43245 42828 43966 44803 48416>,
			<43525 10540 44073 43841 42933 43613 44197 48383>,
			<43625 11968 44245 43793 42500 43639 44238 48903>,
			<43644 12179 44240 43837 42694 43622 44038 49134>,
			<43584 12127 44252 43988 42723 43619 44103 49070>,
			<43607 11275 44249 43969 42627 43618 44417 48743>,
			<43918 11642 44229 44018 41220 43629 44290 48782>,
			<44006  8807 44231 44007 41019 43619 41661 47169>,
			<43993  8972 44226 44014 41621 43620 41679 47674>,
			<43783  8315 44277 43922 44633 43645 41472 42910>,
			<43902  8505 44272 43931 43285 43633 41582 41310>,
			<43227  9363 44281 43909 43866 43637 41786 41147>,
			<43431  9695 44263 44004 43801 43587 41628 41819>,
			<43327  9473 44256 44015 44013 43609 41919 41951>,
			<44208 14889 44182 43949 43914 43942 41085 41563>,
			<41956 14561 44162 43597 43994 43910 44108 41914>,
			<42537 16046 44222 43951 43044 43909 44809 41106>,
			<42269 16366 44884 43947 43879 43912 44863 41972>,
			<47169 15478 44870 43604 43976 43961 44464 41588>,
			<49142 12815 44919 43919 43169 43951 44212 41735>,
			<45627 14012 44900 43787 43434 43632 44696 41371>,
			<45423 13794 44818 43833 43989 43640 44235 41772>,
			<46892  2966 44802 43989 43928 43634 44375 41907>,
			<46458  2395 44854 44017 43948 43637 41952 41476>,
			<35246  3442 44833 43911 43951 43585 41968 41676>,
			<36692   491 45023 43960 43931 43942 44358 41712>,
			<36282  1583 44993 43936 44010 43955 44486 41717>;
	};
};
